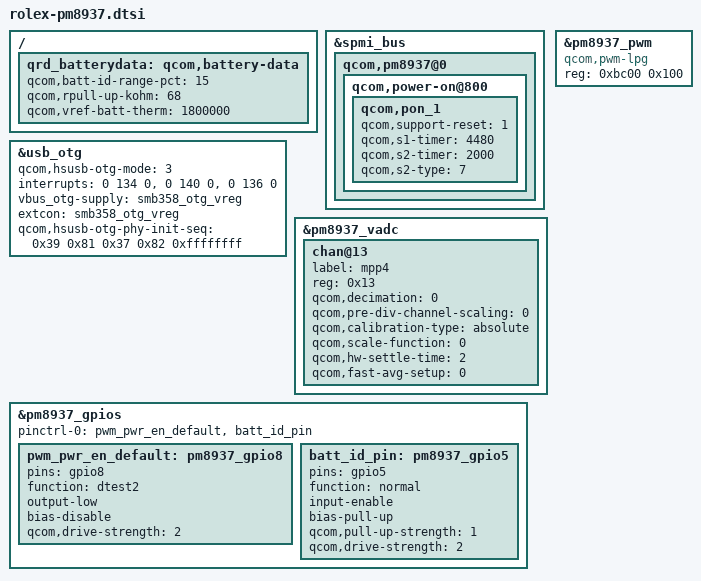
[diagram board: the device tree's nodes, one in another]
&spmi_bus {
      qcom,pm8937@0 {
              qcom,power-on@800 {
	              qcom,pon_1 {
		              qcom,support-reset = <1>;
			      qcom,s1-timer = <4480>;
			      qcom,s2-timer = <2000>;
		              qcom,s2-type = <7>;
        	      };
	      };
       };
};

&usb_otg {
	qcom,hsusb-otg-mode = <3>;
	interrupts = <0 134 0>,<0 140 0>,<0 136 0>;
	interrupt-names = "core_irq", "async_irq", "phy_irq";
	vbus_otg-supply = <&smb358_otg_vreg>;
	extcon = <&smb358_otg_vreg>;
	qcom,hsusb-otg-phy-init-seq =
		<0x39 0x81 0x37 0x82 0xffffffff>;
};

&pm8937_vadc{
	chan@13 {
		label = "mpp4";
		reg = <0x13>;
		qcom,decimation = <0>;
		qcom,pre-div-channel-scaling = <0>;
		qcom,calibration-type = "absolute";
		qcom,scale-function = <0>;
		qcom,hw-settle-time = <2>;
		qcom,fast-avg-setup = <0>;
	};
};

&pm8937_gpios {
	pinctrl-names = "default";
	pinctrl-0 = <&pwm_pwr_en_default &batt_id_pin>;
	pwm_pwr_en_default: pm8937_gpio8 {
		pins = "gpio8";
		function = "dtest2";
		output-low;
		bias-disable;
		qcom,drive-strength = <2>;
		status = "okay";
	};

	batt_id_pin: pm8937_gpio5 {
		pins = "gpio5";
		function = "normal";
		input-enable;
		bias-pull-up;
		qcom,pull-up-strength = <1>;
		qcom,drive-strength = <2>;
		status = "okay";
	};
};

&pm8937_pwm {
	status = "ok";
	compatible = "qcom,pwm-lpg";
	reg = <0xbc00 0x100>;
	reg-names = "lpg-base";
	#pwm-cells = <2>;
};

/ {
qrd_batterydata: qcom,battery-data {
		qcom,batt-id-range-pct = <15>;
		qcom,rpull-up-kohm = <68>;
		qcom,vref-batt-therm = <1800000>;

		#include "batterydata-wingtech-feimaotui_SONY-4v4-3030mah.dtsi"
		#include "batterydata-wingtech-xingwangda_ATL-4v4-3030mah.dtsi"

	};

};
